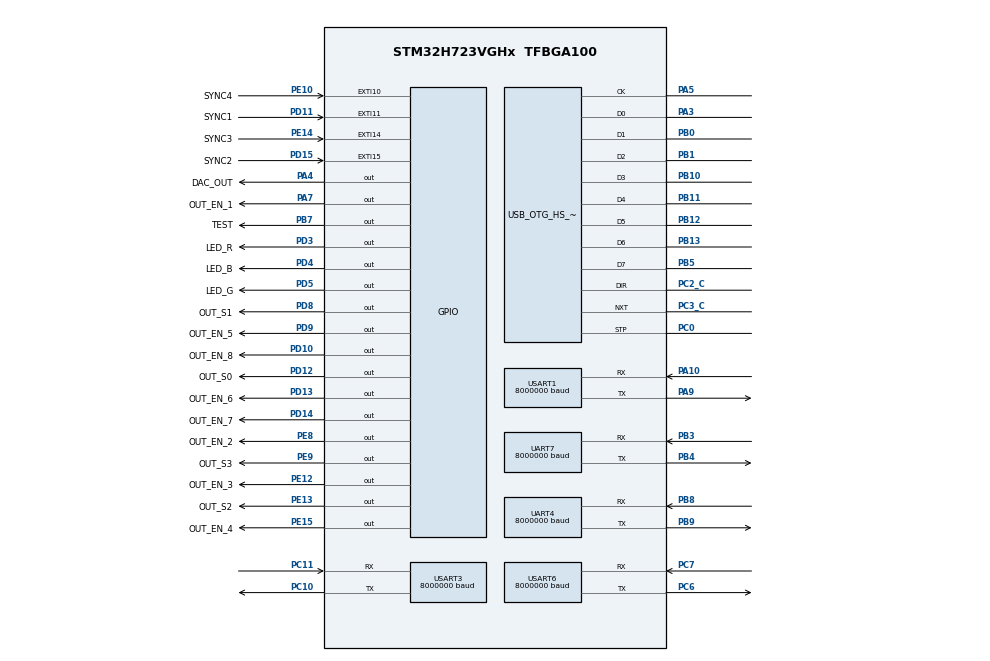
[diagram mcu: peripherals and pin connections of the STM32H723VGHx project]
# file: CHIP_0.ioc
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CORTEX_M7.AccessPermission_S-Cortex_Memory_Protection_Unit_Region1_Settings_S=MPU_REGION_FULL_ACCESS
CORTEX_M7.BaseAddress_S-Cortex_Memory_Protection_Unit_Region1_Settings_S=0x30000000
CORTEX_M7.CPU_DCache=Enabled
CORTEX_M7.CPU_ICache=Enabled
CORTEX_M7.Enable_S-Cortex_Memory_Protection_Unit_Region1_Settings_S=MPU_REGION_ENABLE
CORTEX_M7.IsBufferable_S-Cortex_Memory_Protection_Unit_Region1_Settings_S=MPU_ACCESS_BUFFERABLE
CORTEX_M7.IsShareable_S-Cortex_Memory_Protection_Unit_Region1_Settings_S=MPU_ACCESS_SHAREABLE
CORTEX_M7.Size_S-Cortex_Memory_Protection_Unit_Region1_Settings_S=MPU_REGION_SIZE_16KB
CORTEX_M7.default_mode_Activation=1
Dma.Request0=UART4_RX
Dma.Request1=UART4_TX
Dma.Request2=UART7_RX
Dma.Request3=UART7_TX
Dma.Request4=USART3_RX
Dma.Request5=USART3_TX
Dma.Request6=USART1_RX
Dma.Request7=USART1_TX
Dma.Request8=USART6_RX
Dma.Request9=USART6_TX
Dma.UART4_RX.0.Direction=DMA_PERIPH_TO_MEMORY
Dma.UART4_RX.0.EventEnable=DISABLE
Dma.UART4_RX.0.FIFOMode=DMA_FIFOMODE_DISABLE
Dma.UART4_RX.0.Instance=DMA1_Stream0
Dma.UART4_RX.0.MemDataAlignment=DMA_MDATAALIGN_BYTE
Dma.UART4_RX.0.MemInc=DMA_MINC_ENABLE
Dma.UART4_RX.0.Mode=DMA_NORMAL
Dma.UART4_RX.0.PeriphDataAlignment=DMA_PDATAALIGN_BYTE
Dma.UART4_RX.0.PeriphInc=DMA_PINC_DISABLE
Dma.UART4_RX.0.Polarity=HAL_DMAMUX_REQ_GEN_RISING
Dma.UART4_RX.0.Priority=DMA_PRIORITY_LOW
Dma.UART4_RX.0.RequestNumber=1
Dma.UART4_RX.0.SignalID=NONE
Dma.UART4_RX.0.SyncEnable=DISABLE
Dma.UART4_RX.0.SyncPolarity=HAL_DMAMUX_SYNC_NO_EVENT
Dma.UART4_RX.0.SyncRequestNumber=1
Dma.UART4_RX.0.SyncSignalID=NONE
Dma.UART4_TX.1.Direction=DMA_MEMORY_TO_PERIPH
Dma.UART4_TX.1.EventEnable=DISABLE
Dma.UART4_TX.1.FIFOMode=DMA_FIFOMODE_DISABLE
Dma.UART4_TX.1.Instance=DMA1_Stream1
Dma.UART4_TX.1.MemDataAlignment=DMA_MDATAALIGN_BYTE
Dma.UART4_TX.1.MemInc=DMA_MINC_ENABLE
Dma.UART4_TX.1.Mode=DMA_NORMAL
Dma.UART4_TX.1.PeriphDataAlignment=DMA_PDATAALIGN_BYTE
Dma.UART4_TX.1.PeriphInc=DMA_PINC_DISABLE
Dma.UART4_TX.1.Polarity=HAL_DMAMUX_REQ_GEN_RISING
Dma.UART4_TX.1.Priority=DMA_PRIORITY_LOW
Dma.UART4_TX.1.RequestNumber=1
Dma.UART4_TX.1.SignalID=NONE
Dma.UART4_TX.1.SyncEnable=DISABLE
Dma.UART4_TX.1.SyncPolarity=HAL_DMAMUX_SYNC_NO_EVENT
Dma.UART4_TX.1.SyncRequestNumber=1
Dma.UART4_TX.1.SyncSignalID=NONE
Dma.UART7_RX.2.Direction=DMA_PERIPH_TO_MEMORY
Dma.UART7_RX.2.EventEnable=DISABLE
Dma.UART7_RX.2.FIFOMode=DMA_FIFOMODE_DISABLE
Dma.UART7_RX.2.Instance=DMA1_Stream2
Dma.UART7_RX.2.MemDataAlignment=DMA_MDATAALIGN_BYTE
Dma.UART7_RX.2.MemInc=DMA_MINC_ENABLE
Dma.UART7_RX.2.Mode=DMA_NORMAL
Dma.UART7_RX.2.PeriphDataAlignment=DMA_PDATAALIGN_BYTE
Dma.UART7_RX.2.PeriphInc=DMA_PINC_DISABLE
Dma.UART7_RX.2.Polarity=HAL_DMAMUX_REQ_GEN_RISING
Dma.UART7_RX.2.Priority=DMA_PRIORITY_LOW
Dma.UART7_RX.2.RequestNumber=1
Dma.UART7_RX.2.SignalID=NONE
Dma.UART7_RX.2.SyncEnable=DISABLE
Dma.UART7_RX.2.SyncPolarity=HAL_DMAMUX_SYNC_NO_EVENT
Dma.UART7_RX.2.SyncRequestNumber=1
Dma.UART7_RX.2.SyncSignalID=NONE
Dma.UART7_TX.3.Direction=DMA_MEMORY_TO_PERIPH
Dma.UART7_TX.3.EventEnable=DISABLE
Dma.UART7_TX.3.FIFOMode=DMA_FIFOMODE_DISABLE
Dma.UART7_TX.3.Instance=DMA1_Stream3
Dma.UART7_TX.3.MemDataAlignment=DMA_MDATAALIGN_BYTE
Dma.UART7_TX.3.MemInc=DMA_MINC_ENABLE
Dma.UART7_TX.3.Mode=DMA_NORMAL
Dma.UART7_TX.3.PeriphDataAlignment=DMA_PDATAALIGN_BYTE
Dma.UART7_TX.3.PeriphInc=DMA_PINC_DISABLE
Dma.UART7_TX.3.Polarity=HAL_DMAMUX_REQ_GEN_RISING
Dma.UART7_TX.3.Priority=DMA_PRIORITY_LOW
Dma.UART7_TX.3.RequestNumber=1
Dma.UART7_TX.3.SignalID=NONE
Dma.UART7_TX.3.SyncEnable=DISABLE
Dma.UART7_TX.3.SyncPolarity=HAL_DMAMUX_SYNC_NO_EVENT
Dma.UART7_TX.3.SyncRequestNumber=1
Dma.UART7_TX.3.SyncSignalID=NONE
Dma.USART1_RX.6.Direction=DMA_PERIPH_TO_MEMORY
Dma.USART1_RX.6.EventEnable=DISABLE
Dma.USART1_RX.6.FIFOMode=DMA_FIFOMODE_DISABLE
Dma.USART1_RX.6.Instance=DMA1_Stream6
Dma.USART1_RX.6.MemDataAlignment=DMA_MDATAALIGN_BYTE
Dma.USART1_RX.6.MemInc=DMA_MINC_ENABLE
Dma.USART1_RX.6.Mode=DMA_NORMAL
Dma.USART1_RX.6.PeriphDataAlignment=DMA_PDATAALIGN_BYTE
Dma.USART1_RX.6.PeriphInc=DMA_PINC_DISABLE
Dma.USART1_RX.6.Polarity=HAL_DMAMUX_REQ_GEN_RISING
Dma.USART1_RX.6.Priority=DMA_PRIORITY_LOW
Dma.USART1_RX.6.RequestNumber=1
Dma.USART1_RX.6.SignalID=NONE
Dma.USART1_RX.6.SyncEnable=DISABLE
Dma.USART1_RX.6.SyncPolarity=HAL_DMAMUX_SYNC_NO_EVENT
Dma.USART1_RX.6.SyncRequestNumber=1
Dma.USART1_RX.6.SyncSignalID=NONE
Dma.USART1_TX.7.Direction=DMA_MEMORY_TO_PERIPH
Dma.USART1_TX.7.EventEnable=DISABLE
Dma.USART1_TX.7.FIFOMode=DMA_FIFOMODE_DISABLE
Dma.USART1_TX.7.Instance=DMA1_Stream7
Dma.USART1_TX.7.MemDataAlignment=DMA_MDATAALIGN_BYTE
Dma.USART1_TX.7.MemInc=DMA_MINC_ENABLE
Dma.USART1_TX.7.Mode=DMA_NORMAL
Dma.USART1_TX.7.PeriphDataAlignment=DMA_PDATAALIGN_BYTE
Dma.USART1_TX.7.PeriphInc=DMA_PINC_DISABLE
Dma.USART1_TX.7.Polarity=HAL_DMAMUX_REQ_GEN_RISING
Dma.USART1_TX.7.Priority=DMA_PRIORITY_LOW
Dma.USART1_TX.7.RequestNumber=1
Dma.USART1_TX.7.SignalID=NONE
Dma.USART1_TX.7.SyncEnable=DISABLE
Dma.USART1_TX.7.SyncPolarity=HAL_DMAMUX_SYNC_NO_EVENT
Dma.USART1_TX.7.SyncRequestNumber=1
Dma.USART1_TX.7.SyncSignalID=NONE
Dma.USART3_RX.4.Direction=DMA_PERIPH_TO_MEMORY
Dma.USART3_RX.4.EventEnable=DISABLE
Dma.USART3_RX.4.FIFOMode=DMA_FIFOMODE_DISABLE
Dma.USART3_RX.4.Instance=DMA1_Stream4
Dma.USART3_RX.4.MemDataAlignment=DMA_MDATAALIGN_BYTE
Dma.USART3_RX.4.MemInc=DMA_MINC_ENABLE
Dma.USART3_RX.4.Mode=DMA_NORMAL
Dma.USART3_RX.4.PeriphDataAlignment=DMA_PDATAALIGN_BYTE
Dma.USART3_RX.4.PeriphInc=DMA_PINC_DISABLE
Dma.USART3_RX.4.Polarity=HAL_DMAMUX_REQ_GEN_RISING
Dma.USART3_RX.4.Priority=DMA_PRIORITY_LOW
Dma.USART3_RX.4.RequestNumber=1
Dma.USART3_RX.4.SignalID=NONE
Dma.USART3_RX.4.SyncEnable=DISABLE
Dma.USART3_RX.4.SyncPolarity=HAL_DMAMUX_SYNC_NO_EVENT
Dma.USART3_RX.4.SyncRequestNumber=1
Dma.USART3_RX.4.SyncSignalID=NONE
Dma.USART3_TX.5.Direction=DMA_MEMORY_TO_PERIPH
Dma.USART3_TX.5.EventEnable=DISABLE
Dma.USART3_TX.5.FIFOMode=DMA_FIFOMODE_DISABLE
Dma.USART3_TX.5.Instance=DMA1_Stream5
Dma.USART3_TX.5.MemDataAlignment=DMA_MDATAALIGN_BYTE
Dma.USART3_TX.5.MemInc=DMA_MINC_ENABLE
Dma.USART3_TX.5.Mode=DMA_NORMAL
Dma.USART3_TX.5.PeriphDataAlignment=DMA_PDATAALIGN_BYTE
Dma.USART3_TX.5.PeriphInc=DMA_PINC_DISABLE
Dma.USART3_TX.5.Polarity=HAL_DMAMUX_REQ_GEN_RISING
Dma.USART3_TX.5.Priority=DMA_PRIORITY_LOW
Dma.USART3_TX.5.RequestNumber=1
Dma.USART3_TX.5.SignalID=NONE
Dma.USART3_TX.5.SyncEnable=DISABLE
Dma.USART3_TX.5.SyncPolarity=HAL_DMAMUX_SYNC_NO_EVENT
Dma.USART3_TX.5.SyncRequestNumber=1
Dma.USART3_TX.5.SyncSignalID=NONE
Dma.USART6_RX.8.Direction=DMA_PERIPH_TO_MEMORY
Dma.USART6_RX.8.EventEnable=DISABLE
Dma.USART6_RX.8.FIFOMode=DMA_FIFOMODE_DISABLE
Dma.USART6_RX.8.Instance=DMA2_Stream0
Dma.USART6_RX.8.MemDataAlignment=DMA_MDATAALIGN_BYTE
Dma.USART6_RX.8.MemInc=DMA_MINC_ENABLE
Dma.USART6_RX.8.Mode=DMA_NORMAL
Dma.USART6_RX.8.PeriphDataAlignment=DMA_PDATAALIGN_BYTE
Dma.USART6_RX.8.PeriphInc=DMA_PINC_DISABLE
Dma.USART6_RX.8.Polarity=HAL_DMAMUX_REQ_GEN_RISING
Dma.USART6_RX.8.Priority=DMA_PRIORITY_LOW
Dma.USART6_RX.8.RequestNumber=1
Dma.USART6_RX.8.SignalID=NONE
Dma.USART6_RX.8.SyncEnable=DISABLE
Dma.USART6_RX.8.SyncPolarity=HAL_DMAMUX_SYNC_NO_EVENT
Dma.USART6_RX.8.SyncRequestNumber=1
Dma.USART6_RX.8.SyncSignalID=NONE
Dma.USART6_TX.9.Direction=DMA_MEMORY_TO_PERIPH
Dma.USART6_TX.9.EventEnable=DISABLE
Dma.USART6_TX.9.FIFOMode=DMA_FIFOMODE_DISABLE
Dma.USART6_TX.9.Instance=DMA2_Stream1
Dma.USART6_TX.9.MemDataAlignment=DMA_MDATAALIGN_BYTE
Dma.USART6_TX.9.MemInc=DMA_MINC_ENABLE
Dma.USART6_TX.9.Mode=DMA_NORMAL
Dma.USART6_TX.9.PeriphDataAlignment=DMA_PDATAALIGN_BYTE
Dma.USART6_TX.9.PeriphInc=DMA_PINC_DISABLE
Dma.USART6_TX.9.Polarity=HAL_DMAMUX_REQ_GEN_RISING
Dma.USART6_TX.9.Priority=DMA_PRIORITY_LOW
Dma.USART6_TX.9.RequestNumber=1
Dma.USART6_TX.9.SignalID=NONE
Dma.USART6_TX.9.SyncEnable=DISABLE
Dma.USART6_TX.9.SyncPolarity=HAL_DMAMUX_SYNC_NO_EVENT
Dma.USART6_TX.9.SyncRequestNumber=1
Dma.USART6_TX.9.SyncSignalID=NONE
Mcu.Family=STM32H7
Mcu.Name=STM32H723VGHx
Mcu.Package=TFBGA100
NVIC.DMA1_Stream0_IRQn=true\:0\:0\:false\:false\:true\:false\:true\:true
NVIC.DMA1_Stream1_IRQn=true\:0\:0\:false\:false\:true\:false\:true\:true
NVIC.DMA1_Stream2_IRQn=true\:0\:0\:false\:false\:true\:false\:true\:true
NVIC.DMA1_Stream3_IRQn=true\:0\:0\:false\:false\:true\:false\:true\:true
NVIC.DMA1_Stream4_IRQn=true\:0\:0\:false\:false\:true\:false\:true\:true
NVIC.DMA1_Stream5_IRQn=true\:0\:0\:false\:false\:true\:false\:true\:true
NVIC.DMA1_Stream6_IRQn=true\:0\:0\:false\:false\:true\:false\:true\:true
NVIC.DMA1_Stream7_IRQn=true\:0\:0\:false\:false\:true\:false\:true\:true
NVIC.DMA2_Stream0_IRQn=true\:0\:0\:false\:false\:true\:false\:true\:true
NVIC.DMA2_Stream1_IRQn=true\:0\:0\:false\:false\:true\:false\:true\:true
NVIC.EXTI15_10_IRQn=true\:0\:0\:false\:false\:true\:true\:true\:true
NVIC.OTG_HS_IRQn=true\:0\:0\:false\:false\:true\:false\:true\:true
NVIC.PriorityGroup=NVIC_PRIORITYGROUP_4
NVIC.UART4_IRQn=true\:0\:0\:false\:false\:true\:false\:true\:true
NVIC.UART7_IRQn=true\:0\:0\:false\:false\:true\:false\:true\:true
NVIC.USART1_IRQn=true\:0\:0\:false\:false\:true\:false\:true\:true
NVIC.USART3_IRQn=true\:0\:0\:false\:false\:true\:false\:true\:true
NVIC.USART6_IRQn=true\:0\:0\:false\:false\:true\:false\:true\:true
PA10.Mode=Asynchronous
PA10.Signal=USART1_RX
PA13(JTMS/SWDIO).Mode=Serial_Wire
PA13(JTMS/SWDIO).Signal=DEBUG_JTMS-SWDIO
PA14(JTCK/SWCLK).Mode=Serial_Wire
PA14(JTCK/SWCLK).Signal=DEBUG_JTCK-SWCLK
PA3.Mode=Device_HS
PA3.Signal=USB_OTG_HS_ULPI_D0
PA4.GPIO_Label=DAC_OUT
PA4.PinState=GPIO_PIN_SET
PA4.Signal=GPIO_Output
PA5.Mode=Device_HS
PA5.Signal=USB_OTG_HS_ULPI_CK
PA7.GPIO_Label=OUT_EN_1
PA7.GPIO_Speed=GPIO_SPEED_FREQ_VERY_HIGH
PA7.PinState=GPIO_PIN_SET
PA7.Signal=GPIO_Output
PA9.Mode=Asynchronous
PA9.Signal=USART1_TX
PB0.Mode=Device_HS
PB0.Signal=USB_OTG_HS_ULPI_D1
PB1.Mode=Device_HS
PB1.Signal=USB_OTG_HS_ULPI_D2
PB10.Mode=Device_HS
PB10.Signal=USB_OTG_HS_ULPI_D3
PB11.Mode=Device_HS
PB11.Signal=USB_OTG_HS_ULPI_D4
PB12.Mode=Device_HS
PB12.Signal=USB_OTG_HS_ULPI_D5
PB13.Mode=Device_HS
PB13.Signal=USB_OTG_HS_ULPI_D6
PB3(JTDO/TRACESWO).Mode=Asynchronous
PB3(JTDO/TRACESWO).Signal=UART7_RX
PB4(NJTRST).Mode=Asynchronous
PB4(NJTRST).Signal=UART7_TX
PB5.Mode=Device_HS
PB5.Signal=USB_OTG_HS_ULPI_D7
PB7.GPIO_FM7=__NULL
PB7.GPIO_Label=TEST
PB7.GPIO_Speed=GPIO_SPEED_FREQ_VERY_HIGH
PB7.Signal=GPIO_Output
PB8.Mode=Asynchronous
PB8.Signal=UART4_RX
PB9.Mode=Asynchronous
PB9.Signal=UART4_TX
PC0.Mode=Device_HS
PC0.Signal=USB_OTG_HS_ULPI_STP
PC10.Mode=Asynchronous
PC10.Signal=USART3_TX
PC11.Mode=Asynchronous
PC11.Signal=USART3_RX
PC2_C.Mode=Device_HS
PC2_C.Signal=USB_OTG_HS_ULPI_DIR
PC3_C.Mode=Device_HS
PC3_C.Signal=USB_OTG_HS_ULPI_NXT
PC6.Mode=Asynchronous
PC6.Signal=USART6_TX
PC7.Mode=Asynchronous
PC7.Signal=USART6_RX
PD10.GPIO_Label=OUT_EN_8
PD10.GPIO_Speed=GPIO_SPEED_FREQ_VERY_HIGH
PD10.PinState=GPIO_PIN_SET
PD10.Signal=GPIO_Output
PD11.GPIO_Label=SYNC1
PD11.GPIO_ModeDefaultEXTI=GPIO_MODE_IT_RISING
PD11.Signal=GPXTI11
PD12.GPIO_Label=OUT_S0
PD12.GPIO_Speed=GPIO_SPEED_FREQ_VERY_HIGH
PD12.Signal=GPIO_Output
PD13.GPIO_Label=OUT_EN_6
PD13.GPIO_Speed=GPIO_SPEED_FREQ_VERY_HIGH
PD13.PinState=GPIO_PIN_SET
PD13.Signal=GPIO_Output
PD14.GPIO_Label=OUT_EN_7
PD14.GPIO_Speed=GPIO_SPEED_FREQ_VERY_HIGH
PD14.PinState=GPIO_PIN_SET
PD14.Signal=GPIO_Output
PD15.GPIO_Label=SYNC2
PD15.Signal=GPXTI15
PD3.GPIO_Label=LED_R
PD3.PinState=GPIO_PIN_SET
PD3.Signal=GPIO_Output
PD4.GPIO_Label=LED_B
PD4.PinState=GPIO_PIN_SET
PD4.Signal=GPIO_Output
PD5.GPIO_Label=LED_G
PD5.PinState=GPIO_PIN_SET
PD5.Signal=GPIO_Output
PD8.GPIO_Label=OUT_S1
PD8.GPIO_Speed=GPIO_SPEED_FREQ_VERY_HIGH
PD8.Signal=GPIO_Output
PD9.GPIO_Label=OUT_EN_5
PD9.GPIO_Speed=GPIO_SPEED_FREQ_VERY_HIGH
PD9.PinState=GPIO_PIN_SET
PD9.Signal=GPIO_Output
PE10.GPIO_Label=SYNC4
PE10.Signal=GPXTI10
PE12.GPIO_Label=OUT_EN_3
PE12.GPIO_Speed=GPIO_SPEED_FREQ_VERY_HIGH
PE12.PinState=GPIO_PIN_SET
PE12.Signal=GPIO_Output
PE13.GPIO_Label=OUT_S2
PE13.GPIO_Speed=GPIO_SPEED_FREQ_VERY_HIGH
PE13.Signal=GPIO_Output
PE14.GPIO_Label=SYNC3
PE14.Signal=GPXTI14
PE15.GPIO_Label=OUT_EN_4
PE15.GPIO_Speed=GPIO_SPEED_FREQ_VERY_HIGH
PE15.PinState=GPIO_PIN_SET
PE15.Signal=GPIO_Output
PE8.GPIO_Label=OUT_EN_2
PE8.GPIO_Speed=GPIO_SPEED_FREQ_VERY_HIGH
PE8.PinState=GPIO_PIN_SET
PE8.Signal=GPIO_Output
PE9.GPIO_Label=OUT_S3
PE9.GPIO_Speed=GPIO_SPEED_FREQ_VERY_HIGH
PE9.PinState=GPIO_PIN_RESET
PE9.Signal=GPIO_Output
PH0-OSC_IN.Mode=HSE-External-Oscillator
PH0-OSC_IN.Signal=RCC_OSC_IN
PH1-OSC_OUT.Mode=HSE-External-Oscillator
PH1-OSC_OUT.Signal=RCC_OSC_OUT
ProjectManager.HeapSize=0x200
ProjectManager.StackSize=0x400
ProjectManager.TargetToolchain=MDK-ARM V5.32
RCC.ADCFreq_Value=50390625
RCC.APB1Freq_Value=137500000
RCC.APB2Freq_Value=137500000
RCC.APB3Freq_Value=137500000
RCC.APB4Freq_Value=137500000
RCC.CortexFreq_Value=550000000
RCC.D1PPRE=RCC_APB3_DIV2
RCC.D2PPRE1=RCC_APB1_DIV2
RCC.D2PPRE2=RCC_APB2_DIV2
RCC.D3PPRE=RCC_APB4_DIV2
RCC.DIVM1=2
RCC.DIVN1=44
RCC.DIVP1=1
RCC.HCLKFreq_Value=275000000
RCC.HPRE=RCC_HCLK_DIV2
RCC.PLL2FRACN=0
RCC.PLL3FRACN=0
RCC.PLLFRACN=0
RCC.PLLSourceVirtual=RCC_PLLSOURCE_HSE
RCC.SYSCLKFreq_VALUE=550000000
RCC.SYSCLKSource=RCC_SYSCLKSOURCE_PLLCLK
RCC.USBCLockSelection=RCC_USBCLKSOURCE_HSI48
RCC.USBFreq_Value=48000000
UART4.BaudRate=8000000
UART7.BaudRate=8000000
USART1.BaudRate=8000000
USART1.VirtualMode-Asynchronous=VM_ASYNC
USART3.BaudRate=8000000
USART3.VirtualMode-Asynchronous=VM_ASYNC
USART6.BaudRate=8000000
USART6.VirtualMode=VM_ASYNC
USB_DEVICE.CLASS_NAME_HS=CDC
USB_DEVICE.VirtualMode=Cdc
USB_DEVICE.VirtualModeHS=Cdc_HS
USB_OTG_HS.VirtualMode-Device_HS=Device_HS
VP_MEMORYMAP_VS_MEMORYMAP.Mode=CurAppReg
VP_USB_DEVICE_VS_USB_DEVICE_CDC_HS.Mode=CDC_HS
board=custom

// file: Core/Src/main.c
/* USER CODE BEGIN Header */
/**
 ******************************************************************************
 * @file           : main.c
 * @brief          : Main program body
 ******************************************************************************
 * @attention
 *
 * Copyright (c) 2026 STMicroelectronics.
 * All rights reserved.

 *
 * This software is licensed under terms that can be found in the LICENSE file
 * in the root directory of this software component.
 * If no LICENSE file comes with this software, it is provided AS-IS.
 *
 ******************************************************************************
 */
/* USER CODE END Header */
#include "main.h"
#include "dma.h"
#include "gpio.h"
#include "usart.h"
#include "usb_device.h"

/* USER CODE BEGIN Includes */
#include <stdio.h>

#include "user_comm.h"
/* USER CODE END Includes */

void SystemClock_Config(void);
static void MPU_Config(void);

int main(void)
{

    /* MPU Configuration--------------------------------------------------------*/
    MPU_Config();

    /* Enable the CPU Cache */

    /* Enable I-Cache---------------------------------------------------------*/
    SCB_EnableICache();

    /* Enable D-Cache---------------------------------------------------------*/
    SCB_EnableDCache();

    /* MCU Configuration--------------------------------------------------------*/

    /* Reset of all peripherals, Initializes the Flash interface and the Systick. */
    HAL_Init();

    /* Configure the system clock */
    SystemClock_Config();

    /* USER CODE BEGIN SysInit */
    HAL_Delay(200U);
    /* USER CODE END SysInit */

    /* Initialize all configured peripherals */
    MX_GPIO_Init();
    MX_DMA_Init();
    MX_UART4_Init();
    MX_UART7_Init();
    MX_USART3_UART_Init();
    MX_USART1_UART_Init();
    MX_USART6_UART_Init();
    MX_USB_DEVICE_Init();
    /* USER CODE BEGIN 2 */

    delay_init();

    all_wave_ch_disable();

    if (comm_init() != HAL_OK)
    {
        Error_Handler();
    }

    HAL_Delay(5000);

    printf("USB CDC printf ready\r\n");

    /* USER CODE END 2 */

    /* Infinite loop */
    /* USER CODE BEGIN WHILE */
    while (1)
    {

        test_led();

        uart1_tx_test();

        // uart1_tx_test_without_cdc();
         // main_task_sync_test();

        // sync_test();
        // comm_process();

        // main_task();

        /* USER CODE END WHILE */

    }
}

void SystemClock_Config(void)
{
    RCC_OscInitTypeDef RCC_OscInitStruct = {0};
    RCC_ClkInitTypeDef RCC_ClkInitStruct = {0};

    /** Supply configuration update enable
     */
    HAL_PWREx_ConfigSupply(PWR_LDO_SUPPLY);

    /** Configure the main internal regulator output voltage
     */
    __HAL_PWR_VOLTAGESCALING_CONFIG(PWR_REGULATOR_VOLTAGE_SCALE0);

    while (!__HAL_PWR_GET_FLAG(PWR_FLAG_VOSRDY))
    {
    }

    /** Initializes the RCC Oscillators according to the specified parameters
     * in the RCC_OscInitTypeDef structure.
     */
    RCC_OscInitStruct.OscillatorType = RCC_OSCILLATORTYPE_HSI48 | RCC_OSCILLATORTYPE_HSE;
    RCC_OscInitStruct.HSEState = RCC_HSE_ON;
    RCC_OscInitStruct.HSI48State = RCC_HSI48_ON;
    RCC_OscInitStruct.PLL.PLLState = RCC_PLL_ON;
    RCC_OscInitStruct.PLL.PLLSource = RCC_PLLSOURCE_HSE;
    RCC_OscInitStruct.PLL.PLLM = 2;
    RCC_OscInitStruct.PLL.PLLN = 44;
    RCC_OscInitStruct.PLL.PLLP = 1;
    RCC_OscInitStruct.PLL.PLLQ = 2;
    RCC_OscInitStruct.PLL.PLLR = 2;
    RCC_OscInitStruct.PLL.PLLRGE = RCC_PLL1VCIRANGE_3;
    RCC_OscInitStruct.PLL.PLLVCOSEL = RCC_PLL1VCOWIDE;
    RCC_OscInitStruct.PLL.PLLFRACN = 0;
    if (HAL_RCC_OscConfig(&RCC_OscInitStruct) != HAL_OK)
    {
        Error_Handler();
    }

    /** Initializes the CPU, AHB and APB buses clocks
     */
    RCC_ClkInitStruct.ClockType = RCC_CLOCKTYPE_HCLK | RCC_CLOCKTYPE_SYSCLK | RCC_CLOCKTYPE_PCLK1 | RCC_CLOCKTYPE_PCLK2 | RCC_CLOCKTYPE_D3PCLK1 | RCC_CLOCKTYPE_D1PCLK1;
    RCC_ClkInitStruct.SYSCLKSource = RCC_SYSCLKSOURCE_PLLCLK;
    RCC_ClkInitStruct.SYSCLKDivider = RCC_SYSCLK_DIV1;
    RCC_ClkInitStruct.AHBCLKDivider = RCC_HCLK_DIV2;
    RCC_ClkInitStruct.APB3CLKDivider = RCC_APB3_DIV2;
    RCC_ClkInitStruct.APB1CLKDivider = RCC_APB1_DIV2;
    RCC_ClkInitStruct.APB2CLKDivider = RCC_APB2_DIV2;
    RCC_ClkInitStruct.APB4CLKDivider = RCC_APB4_DIV2;

    if (HAL_RCC_ClockConfig(&RCC_ClkInitStruct, FLASH_LATENCY_3) != HAL_OK)
    {
        Error_Handler();
    }
}

/* MPU Configuration */

void MPU_Config(void)
{
    MPU_Region_InitTypeDef MPU_InitStruct = {0};

    /* Disables the MPU */
    HAL_MPU_Disable();

    /** Initializes and configures the Region and the memory to be protected
     */
    MPU_InitStruct.Enable = MPU_REGION_ENABLE;
    MPU_InitStruct.Number = MPU_REGION_NUMBER0;
    MPU_InitStruct.BaseAddress = 0x0;
    MPU_InitStruct.Size = MPU_REGION_SIZE_4GB;
    MPU_InitStruct.SubRegionDisable = 0x87;
    MPU_InitStruct.TypeExtField = MPU_TEX_LEVEL0;
    MPU_InitStruct.AccessPermission = MPU_REGION_NO_ACCESS;
    MPU_InitStruct.DisableExec = MPU_INSTRUCTION_ACCESS_DISABLE;
    MPU_InitStruct.IsShareable = MPU_ACCESS_SHAREABLE;
    MPU_InitStruct.IsCacheable = MPU_ACCESS_NOT_CACHEABLE;
    MPU_InitStruct.IsBufferable = MPU_ACCESS_NOT_BUFFERABLE;

    HAL_MPU_ConfigRegion(&MPU_InitStruct);

    /** Initializes and configures the Region and the memory to be protected
     */
    MPU_InitStruct.Number = MPU_REGION_NUMBER1;
    MPU_InitStruct.BaseAddress = 0x30000000;
    MPU_InitStruct.Size = MPU_REGION_SIZE_16KB;
    MPU_InitStruct.SubRegionDisable = 0x0;
    MPU_InitStruct.AccessPermission = MPU_REGION_FULL_ACCESS;
    MPU_InitStruct.DisableExec = MPU_INSTRUCTION_ACCESS_ENABLE;
    MPU_InitStruct.IsBufferable = MPU_ACCESS_BUFFERABLE;

    HAL_MPU_ConfigRegion(&MPU_InitStruct);
    /* Enables the MPU */
    HAL_MPU_Enable(MPU_PRIVILEGED_DEFAULT);
}

void Error_Handler(void)
{
    /* USER CODE BEGIN Error_Handler_Debug */
    /* User can add his own implementation to report the HAL error return state
     */
    __disable_irq();
    while (1)
    {
    }
    /* USER CODE END Error_Handler_Debug */
}
#ifdef USE_FULL_ASSERT
/**
 * @brief  Reports the name of the source file and the source line number
 *         where the assert_param error has occurred.
 * @param  file: pointer to the source file name
 * @param  line: assert_param error line source number
 * @retval None
 */
void assert_failed(uint8_t *file, uint32_t line)
{
    /* USER CODE BEGIN 6 */
    /* User can add his own implementation to report the file name and line
       number, ex: printf("Wrong parameters value: file %s on line %d\r\n",
       file, line) */
    /* USER CODE END 6 */
}
#endif /* USE_FULL_ASSERT */
